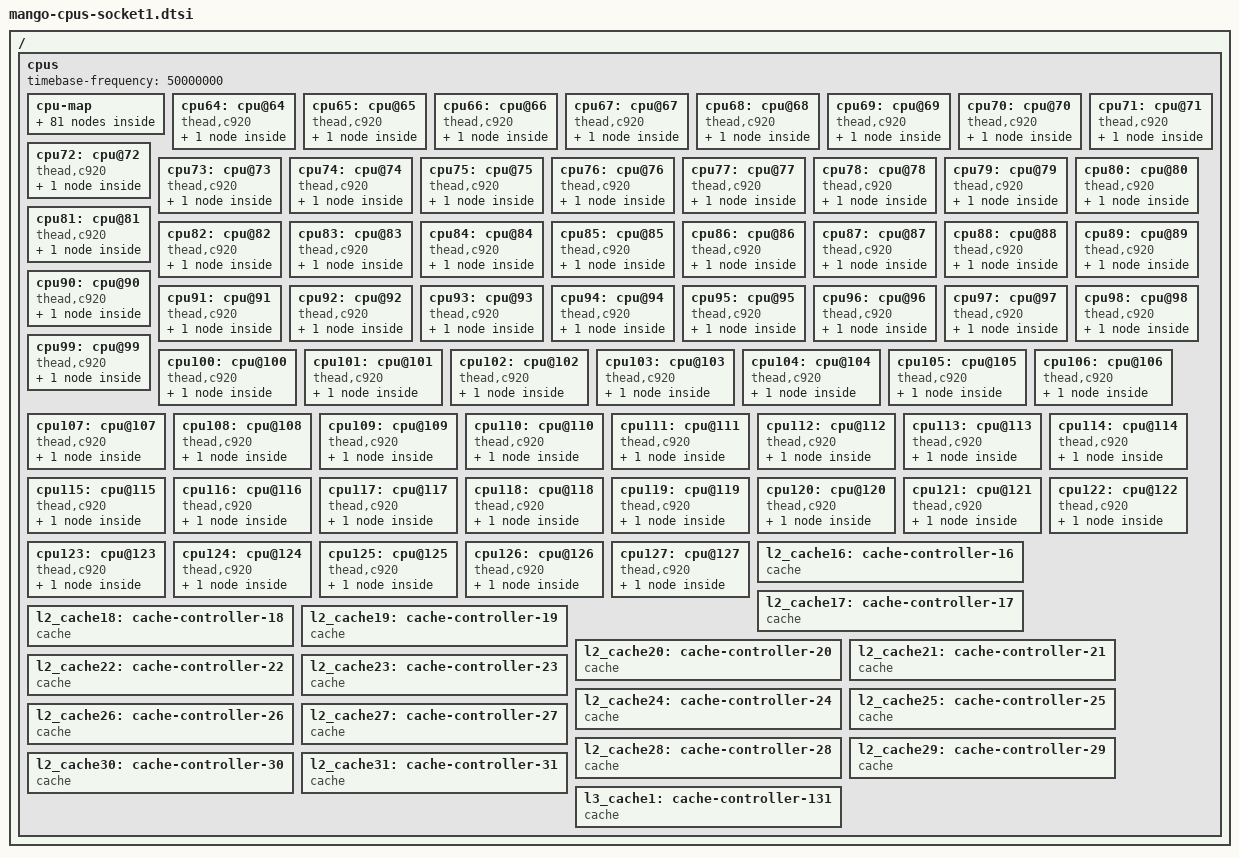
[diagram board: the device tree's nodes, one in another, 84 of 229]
// SPDX-License-Identifier: (GPL-2.0 OR MIT)
/*
 * Copyright (C) 2022 Sophgo Technology Inc. All rights reserved.
 */

/ {
	cpus {
		#address-cells = <1>;
		#size-cells = <0>;
		timebase-frequency = <50000000>;

		cpu-map {
			socket1 {
				cluster0 {
					 core0 {
						cpu = <&cpu64>;
					 };
					 core1 {
						cpu = <&cpu65>;
					 };
					 core2 {
						cpu = <&cpu66>;
					 };
					 core3 {
						cpu = <&cpu67>;
					 };
				};

				cluster1 {
					 core0 {
						cpu = <&cpu68>;
					 };
					 core1 {
						cpu = <&cpu69>;
					 };
					 core2 {
						cpu = <&cpu70>;
					 };
					 core3 {
						cpu = <&cpu71>;
					 };
				};

				cluster2 {
					 core0 {
						cpu = <&cpu80>;
					 };
					 core1 {
						cpu = <&cpu81>;
					 };
					 core2 {
						cpu = <&cpu82>;
					 };
					 core3 {
						cpu = <&cpu83>;
					 };
				};

				cluster3 {
					 core0 {
						cpu = <&cpu84>;
					 };
					 core1 {
						cpu = <&cpu85>;
					 };
					 core2 {
						cpu = <&cpu86>;
					 };
					 core3 {
						cpu = <&cpu87>;
					 };
				};

				cluster4 {
					 core0 {
						cpu = <&cpu72>;
					 };
					 core1 {
						cpu = <&cpu73>;
					 };
					 core2 {
						cpu = <&cpu74>;
					 };
					 core3 {
						cpu = <&cpu75>;
					 };
				};

				cluster5 {
					 core0 {
						cpu = <&cpu76>;
					 };
					 core1 {
						cpu = <&cpu77>;
					 };
					 core2 {
						cpu = <&cpu78>;
					 };
					 core3 {
						cpu = <&cpu79>;
					 };
				};

				cluster6 {
					 core0 {
						cpu = <&cpu88>;
					 };
					 core1 {
						cpu = <&cpu89>;
					 };
					 core2 {
						cpu = <&cpu90>;
					 };
					 core3 {
						cpu = <&cpu91>;
					 };
				};

				cluster7 {
					 core0 {
						cpu = <&cpu92>;
					 };
					 core1 {
						cpu = <&cpu93>;
					 };
					 core2 {
						cpu = <&cpu94>;
					 };
					 core3 {
						cpu = <&cpu95>;
					 };
				};

				cluster8 {
					 core0 {
						cpu = <&cpu96>;
					 };
					 core1 {
						cpu = <&cpu97>;
					 };
					 core2 {
						cpu = <&cpu98>;
					 };
					 core3 {
						cpu = <&cpu99>;
					 };
				};

				cluster9 {
					 core0 {
						cpu = <&cpu100>;
					 };
					 core1 {
						cpu = <&cpu101>;
					 };
					 core2 {
						cpu = <&cpu102>;
					 };
					 core3 {
						cpu = <&cpu103>;
					 };
				};

				cluster10 {
					 core0 {
						cpu = <&cpu112>;
					 };
					 core1 {
						cpu = <&cpu113>;
					 };
					 core2 {
						cpu = <&cpu114>;
					 };
					 core3 {
						cpu = <&cpu115>;
					 };
				};

				cluster11 {
					 core0 {
						cpu = <&cpu116>;
					 };
					 core1 {
						cpu = <&cpu117>;
					 };
					 core2 {
						cpu = <&cpu118>;
					 };
					 core3 {
						cpu = <&cpu119>;
					 };
				};

				cluster12 {
					 core0 {
						cpu = <&cpu104>;
					 };
					 core1 {
						cpu = <&cpu105>;
					 };
					 core2 {
						cpu = <&cpu106>;
					 };
					 core3 {
						cpu = <&cpu107>;
					 };
				};

				cluster13 {
					 core0 {
						cpu = <&cpu108>;
					 };
					 core1 {
						cpu = <&cpu109>;
					 };
					 core2 {
						cpu = <&cpu110>;
					 };
					 core3 {
						cpu = <&cpu111>;
					 };
				};

				cluster14 {
					 core0 {
						cpu = <&cpu120>;
					 };
					 core1 {
						cpu = <&cpu121>;
					 };
					 core2 {
						cpu = <&cpu122>;
					 };
					 core3 {
						cpu = <&cpu123>;
					 };
				};

				cluster15 {
					 core0 {
						cpu = <&cpu124>;
					 };
					 core1 {
						cpu = <&cpu125>;
					 };
					 core2 {
						cpu = <&cpu126>;
					 };
					 core3 {
						cpu = <&cpu127>;
					 };
				};
			};
		};

		cpu64: cpu@64 {
			compatible = "thead,c920", "riscv";
			device_type = "cpu";
			riscv,isa = "rv64imafdc_xtheadvector";
			riscv,isa-base = "rv64i";
			riscv,isa-extensions = "i", "m", "a", "f", "d", "c",
					       "zicntr", "zicsr", "zifencei",
					       "zihpm", "xtheadvector";
			reg = <64>;
			i-cache-size = <65536>;
			i-cache-sets = <512>;
			d-cache-block-size = <64>;
			d-cache-size = <65536>;
			d-cache-sets = <512>;
			next-level-cache = <&l2_cache16>;
			mmu-type = "riscv,sv39";
			numa-node-id = <4>;

			cpu64_intc: interrupt-controller {
				compatible = "riscv,cpu-intc";
				interrupt-controller;
				#interrupt-cells = <1>;
			};
		};

		cpu65: cpu@65 {
			compatible = "thead,c920", "riscv";
			device_type = "cpu";
			riscv,isa = "rv64imafdc_xtheadvector";
			riscv,isa-base = "rv64i";
			riscv,isa-extensions = "i", "m", "a", "f", "d", "c",
					       "zicntr", "zicsr", "zifencei",
					       "zihpm", "xtheadvector";
			reg = <65>;
			i-cache-size = <65536>;
			i-cache-sets = <512>;
			d-cache-block-size = <64>;
			d-cache-size = <65536>;
			d-cache-sets = <512>;
			next-level-cache = <&l2_cache16>;
			mmu-type = "riscv,sv39";
			numa-node-id = <4>;

			cpu65_intc: interrupt-controller {
				compatible = "riscv,cpu-intc";
				interrupt-controller;
				#interrupt-cells = <1>;
			};
		};

		cpu66: cpu@66 {
			compatible = "thead,c920", "riscv";
			device_type = "cpu";
			riscv,isa = "rv64imafdc_xtheadvector";
			riscv,isa-base = "rv64i";
			riscv,isa-extensions = "i", "m", "a", "f", "d", "c",
					       "zicntr", "zicsr", "zifencei",
					       "zihpm", "xtheadvector";
			reg = <66>;
			i-cache-size = <65536>;
			i-cache-sets = <512>;
			d-cache-block-size = <64>;
			d-cache-size = <65536>;
			d-cache-sets = <512>;
			next-level-cache = <&l2_cache16>;
			mmu-type = "riscv,sv39";
			numa-node-id = <4>;

			cpu66_intc: interrupt-controller {
				compatible = "riscv,cpu-intc";
				interrupt-controller;
				#interrupt-cells = <1>;
			};
		};

		cpu67: cpu@67 {
			compatible = "thead,c920", "riscv";
			device_type = "cpu";
			riscv,isa = "rv64imafdc_xtheadvector";
			riscv,isa-base = "rv64i";
			riscv,isa-extensions = "i", "m", "a", "f", "d", "c",
					       "zicntr", "zicsr", "zifencei",
					       "zihpm", "xtheadvector";
			reg = <67>;
			i-cache-size = <65536>;
			i-cache-sets = <512>;
			d-cache-block-size = <64>;
			d-cache-size = <65536>;
			d-cache-sets = <512>;
			next-level-cache = <&l2_cache16>;
			mmu-type = "riscv,sv39";
			numa-node-id = <4>;

			cpu67_intc: interrupt-controller {
				compatible = "riscv,cpu-intc";
				interrupt-controller;
				#interrupt-cells = <1>;
			};
		};

		cpu68: cpu@68 {
			compatible = "thead,c920", "riscv";
			device_type = "cpu";
			riscv,isa = "rv64imafdc_xtheadvector";
			riscv,isa-base = "rv64i";
			riscv,isa-extensions = "i", "m", "a", "f", "d", "c",
					       "zicntr", "zicsr", "zifencei",
					       "zihpm", "xtheadvector";
			reg = <68>;
			i-cache-size = <65536>;
			i-cache-sets = <512>;
			d-cache-block-size = <64>;
			d-cache-size = <65536>;
			d-cache-sets = <512>;
			next-level-cache = <&l2_cache17>;
			mmu-type = "riscv,sv39";
			numa-node-id = <4>;

			cpu68_intc: interrupt-controller {
				compatible = "riscv,cpu-intc";
				interrupt-controller;
				#interrupt-cells = <1>;
			};
		};

		cpu69: cpu@69 {
			compatible = "thead,c920", "riscv";
			device_type = "cpu";
			riscv,isa = "rv64imafdc_xtheadvector";
			riscv,isa-base = "rv64i";
			riscv,isa-extensions = "i", "m", "a", "f", "d", "c",
					       "zicntr", "zicsr", "zifencei",
					       "zihpm", "xtheadvector";
			reg = <69>;
			i-cache-size = <65536>;
			i-cache-sets = <512>;
			d-cache-block-size = <64>;
			d-cache-size = <65536>;
			d-cache-sets = <512>;
			next-level-cache = <&l2_cache17>;
			mmu-type = "riscv,sv39";
			numa-node-id = <4>;

			cpu69_intc: interrupt-controller {
				compatible = "riscv,cpu-intc";
				interrupt-controller;
				#interrupt-cells = <1>;
			};
		};

		cpu70: cpu@70 {
			compatible = "thead,c920", "riscv";
			device_type = "cpu";
			riscv,isa = "rv64imafdc_xtheadvector";
			riscv,isa-base = "rv64i";
			riscv,isa-extensions = "i", "m", "a", "f", "d", "c",
					       "zicntr", "zicsr", "zifencei",
					       "zihpm", "xtheadvector";
			reg = <70>;
			i-cache-size = <65536>;
			i-cache-sets = <512>;
			d-cache-block-size = <64>;
			d-cache-size = <65536>;
			d-cache-sets = <512>;
			next-level-cache = <&l2_cache17>;
			mmu-type = "riscv,sv39";
			numa-node-id = <4>;

			cpu70_intc: interrupt-controller {
				compatible = "riscv,cpu-intc";
				interrupt-controller;
				#interrupt-cells = <1>;
			};
		};

		cpu71: cpu@71 {
			compatible = "thead,c920", "riscv";
			device_type = "cpu";
			riscv,isa = "rv64imafdc_xtheadvector";
			riscv,isa-base = "rv64i";
			riscv,isa-extensions = "i", "m", "a", "f", "d", "c",
					       "zicntr", "zicsr", "zifencei",
					       "zihpm", "xtheadvector";
			reg = <71>;
			i-cache-size = <65536>;
			i-cache-sets = <512>;
			d-cache-block-size = <64>;
			d-cache-size = <65536>;
			d-cache-sets = <512>;
			next-level-cache = <&l2_cache17>;
			mmu-type = "riscv,sv39";
			numa-node-id = <4>;

			cpu71_intc: interrupt-controller {
				compatible = "riscv,cpu-intc";
				interrupt-controller;
				#interrupt-cells = <1>;
			};
		};

		cpu72: cpu@72 {
			compatible = "thead,c920", "riscv";
			device_type = "cpu";
			riscv,isa = "rv64imafdc_xtheadvector";
			riscv,isa-base = "rv64i";
			riscv,isa-extensions = "i", "m", "a", "f", "d", "c",
					       "zicntr", "zicsr", "zifencei",
					       "zihpm", "xtheadvector";
			reg = <72>;
			i-cache-size = <65536>;
			i-cache-sets = <512>;
			d-cache-block-size = <64>;
			d-cache-size = <65536>;
			d-cache-sets = <512>;
			next-level-cache = <&l2_cache20>;
			mmu-type = "riscv,sv39";
			numa-node-id = <5>;

			cpu72_intc: interrupt-controller {
				compatible = "riscv,cpu-intc";
				interrupt-controller;
				#interrupt-cells = <1>;
			};
		};

		cpu73: cpu@73 {
			compatible = "thead,c920", "riscv";
			device_type = "cpu";
			riscv,isa = "rv64imafdc_xtheadvector";
			riscv,isa-base = "rv64i";
			riscv,isa-extensions = "i", "m", "a", "f", "d", "c",
					       "zicntr", "zicsr", "zifencei",
					       "zihpm", "xtheadvector";
			reg = <73>;
			i-cache-size = <65536>;
			i-cache-sets = <512>;
			d-cache-block-size = <64>;
			d-cache-size = <65536>;
			d-cache-sets = <512>;
			next-level-cache = <&l2_cache20>;
			mmu-type = "riscv,sv39";
			numa-node-id = <5>;

			cpu73_intc: interrupt-controller {
				compatible = "riscv,cpu-intc";
				interrupt-controller;
				#interrupt-cells = <1>;
			};
		};

		cpu74: cpu@74 {
			compatible = "thead,c920", "riscv";
			device_type = "cpu";
			riscv,isa = "rv64imafdc_xtheadvector";
			riscv,isa-base = "rv64i";
			riscv,isa-extensions = "i", "m", "a", "f", "d", "c",
					       "zicntr", "zicsr", "zifencei",
					       "zihpm", "xtheadvector";
			reg = <74>;
			i-cache-size = <65536>;
			i-cache-sets = <512>;
			d-cache-block-size = <64>;
			d-cache-size = <65536>;
			d-cache-sets = <512>;
			next-level-cache = <&l2_cache20>;
			mmu-type = "riscv,sv39";
			numa-node-id = <5>;

			cpu74_intc: interrupt-controller {
				compatible = "riscv,cpu-intc";
				interrupt-controller;
				#interrupt-cells = <1>;
			};
		};

		cpu75: cpu@75 {
			compatible = "thead,c920", "riscv";
			device_type = "cpu";
			riscv,isa = "rv64imafdc_xtheadvector";
			riscv,isa-base = "rv64i";
			riscv,isa-extensions = "i", "m", "a", "f", "d", "c",
					       "zicntr", "zicsr", "zifencei",
					       "zihpm", "xtheadvector";
			reg = <75>;
			i-cache-size = <65536>;
			i-cache-sets = <512>;
			d-cache-block-size = <64>;
			d-cache-size = <65536>;
			d-cache-sets = <512>;
			next-level-cache = <&l2_cache20>;
			mmu-type = "riscv,sv39";
			numa-node-id = <5>;

			cpu75_intc: interrupt-controller {
				compatible = "riscv,cpu-intc";
				interrupt-controller;
				#interrupt-cells = <1>;
			};
		};

		cpu76: cpu@76 {
			compatible = "thead,c920", "riscv";
			device_type = "cpu";
			riscv,isa = "rv64imafdc_xtheadvector";
			riscv,isa-base = "rv64i";
			riscv,isa-extensions = "i", "m", "a", "f", "d", "c",
					       "zicntr", "zicsr", "zifencei",
					       "zihpm", "xtheadvector";
			reg = <76>;
			i-cache-size = <65536>;
			i-cache-sets = <512>;
			d-cache-block-size = <64>;
			d-cache-size = <65536>;
			d-cache-sets = <512>;
			next-level-cache = <&l2_cache21>;
			mmu-type = "riscv,sv39";
			numa-node-id = <5>;

			cpu76_intc: interrupt-controller {
				compatible = "riscv,cpu-intc";
				interrupt-controller;
				#interrupt-cells = <1>;
			};
		};

		cpu77: cpu@77 {
			compatible = "thead,c920", "riscv";
			device_type = "cpu";
			riscv,isa = "rv64imafdc_xtheadvector";
			riscv,isa-base = "rv64i";
			riscv,isa-extensions = "i", "m", "a", "f", "d", "c",
					       "zicntr", "zicsr", "zifencei",
					       "zihpm", "xtheadvector";
			reg = <77>;
			i-cache-size = <65536>;
			i-cache-sets = <512>;
			d-cache-block-size = <64>;
			d-cache-size = <65536>;
			d-cache-sets = <512>;
			next-level-cache = <&l2_cache21>;
			mmu-type = "riscv,sv39";
			numa-node-id = <5>;

			cpu77_intc: interrupt-controller {
				compatible = "riscv,cpu-intc";
				interrupt-controller;
				#interrupt-cells = <1>;
			};
		};

		cpu78: cpu@78 {
			compatible = "thead,c920", "riscv";
			device_type = "cpu";
			riscv,isa = "rv64imafdc_xtheadvector";
			riscv,isa-base = "rv64i";
			riscv,isa-extensions = "i", "m", "a", "f", "d", "c",
					       "zicntr", "zicsr", "zifencei",
					       "zihpm", "xtheadvector";
			reg = <78>;
			i-cache-size = <65536>;
			i-cache-sets = <512>;
			d-cache-block-size = <64>;
			d-cache-size = <65536>;
			d-cache-sets = <512>;
			next-level-cache = <&l2_cache21>;
			mmu-type = "riscv,sv39";
			numa-node-id = <5>;

			cpu78_intc: interrupt-controller {
				compatible = "riscv,cpu-intc";
				interrupt-controller;
				#interrupt-cells = <1>;
			};
		};

		cpu79: cpu@79 {
			compatible = "thead,c920", "riscv";
			device_type = "cpu";
			riscv,isa = "rv64imafdc_xtheadvector";
			riscv,isa-base = "rv64i";
			riscv,isa-extensions = "i", "m", "a", "f", "d", "c",
					       "zicntr", "zicsr", "zifencei",
					       "zihpm", "xtheadvector";
			reg = <79>;
			i-cache-size = <65536>;
			i-cache-sets = <512>;
			d-cache-block-size = <64>;
			d-cache-size = <65536>;
			d-cache-sets = <512>;
			next-level-cache = <&l2_cache21>;
			mmu-type = "riscv,sv39";
			numa-node-id = <5>;

			cpu79_intc: interrupt-controller {
				compatible = "riscv,cpu-intc";
				interrupt-controller;
				#interrupt-cells = <1>;
			};
		};

		cpu80: cpu@80 {
			compatible = "thead,c920", "riscv";
			device_type = "cpu";
			riscv,isa = "rv64imafdc_xtheadvector";
			riscv,isa-base = "rv64i";
			riscv,isa-extensions = "i", "m", "a", "f", "d", "c",
					       "zicntr", "zicsr", "zifencei",
					       "zihpm", "xtheadvector";
			reg = <80>;
			i-cache-size = <65536>;
			i-cache-sets = <512>;
			d-cache-block-size = <64>;
			d-cache-size = <65536>;
			d-cache-sets = <512>;
			next-level-cache = <&l2_cache18>;
			mmu-type = "riscv,sv39";
			numa-node-id = <4>;

			cpu80_intc: interrupt-controller {
				compatible = "riscv,cpu-intc";
				interrupt-controller;
				#interrupt-cells = <1>;
			};
		};

		cpu81: cpu@81 {
			compatible = "thead,c920", "riscv";
			device_type = "cpu";
			riscv,isa = "rv64imafdc_xtheadvector";
			riscv,isa-base = "rv64i";
			riscv,isa-extensions = "i", "m", "a", "f", "d", "c",
					       "zicntr", "zicsr", "zifencei",
					       "zihpm", "xtheadvector";
			reg = <81>;
			i-cache-size = <65536>;
			i-cache-sets = <512>;
			d-cache-block-size = <64>;
			d-cache-size = <65536>;
			d-cache-sets = <512>;
			next-level-cache = <&l2_cache18>;
			mmu-type = "riscv,sv39";
			numa-node-id = <4>;

			cpu81_intc: interrupt-controller {
				compatible = "riscv,cpu-intc";
				interrupt-controller;
				#interrupt-cells = <1>;
			};
		};

		cpu82: cpu@82 {
			compatible = "thead,c920", "riscv";
			device_type = "cpu";
			riscv,isa = "rv64imafdc_xtheadvector";
			riscv,isa-base = "rv64i";
			riscv,isa-extensions = "i", "m", "a", "f", "d", "c",
					       "zicntr", "zicsr", "zifencei",
					       "zihpm", "xtheadvector";
			reg = <82>;
			i-cache-size = <65536>;
			i-cache-sets = <512>;
			d-cache-block-size = <64>;
			d-cache-size = <65536>;
			d-cache-sets = <512>;
			next-level-cache = <&l2_cache18>;
			mmu-type = "riscv,sv39";
			numa-node-id = <4>;

			cpu82_intc: interrupt-controller {
				compatible = "riscv,cpu-intc";
				interrupt-controller;
				#interrupt-cells = <1>;
			};
		};

		cpu83: cpu@83 {
			compatible = "thead,c920", "riscv";
			device_type = "cpu";
			riscv,isa = "rv64imafdc_xtheadvector";
			riscv,isa-base = "rv64i";
			riscv,isa-extensions = "i", "m", "a", "f", "d", "c",
					       "zicntr", "zicsr", "zifencei",
					       "zihpm", "xtheadvector";
			reg = <83>;
			i-cache-size = <65536>;
			i-cache-sets = <512>;
			d-cache-block-size = <64>;
			d-cache-size = <65536>;
			d-cache-sets = <512>;
			next-level-cache = <&l2_cache18>;
			mmu-type = "riscv,sv39";
			numa-node-id = <4>;

			cpu83_intc: interrupt-controller {
				compatible = "riscv,cpu-intc";
				interrupt-controller;
				#interrupt-cells = <1>;
			};
		};

		cpu84: cpu@84 {
			compatible = "thead,c920", "riscv";
			device_type = "cpu";
			riscv,isa = "rv64imafdc_xtheadvector";
			riscv,isa-base = "rv64i";
			riscv,isa-extensions = "i", "m", "a", "f", "d", "c",
					       "zicntr", "zicsr", "zifencei",
					       "zihpm", "xtheadvector";
			reg = <84>;
			i-cache-size = <65536>;
			i-cache-sets = <512>;
			d-cache-block-size = <64>;
			d-cache-size = <65536>;
			d-cache-sets = <512>;
			next-level-cache = <&l2_cache19>;
			mmu-type = "riscv,sv39";
			numa-node-id = <4>;

			cpu84_intc: interrupt-controller {
				compatible = "riscv,cpu-intc";
				interrupt-controller;
				#interrupt-cells = <1>;
			};
		};

		cpu85: cpu@85 {
			compatible = "thead,c920", "riscv";
			device_type = "cpu";
			riscv,isa = "rv64imafdc_xtheadvector";
			riscv,isa-base = "rv64i";
			riscv,isa-extensions = "i", "m", "a", "f", "d", "c",
					       "zicntr", "zicsr", "zifencei",
					       "zihpm", "xtheadvector";
			reg = <85>;
			i-cache-size = <65536>;
			i-cache-sets = <512>;
			d-cache-block-size = <64>;
			d-cache-size = <65536>;
			d-cache-sets = <512>;
			next-level-cache = <&l2_cache19>;
			mmu-type = "riscv,sv39";
			numa-node-id = <4>;

			cpu85_intc: interrupt-controller {
				compatible = "riscv,cpu-intc";
				interrupt-controller;
				#interrupt-cells = <1>;
			};
		};

		cpu86: cpu@86 {
			compatible = "thead,c920", "riscv";
			device_type = "cpu";
			riscv,isa = "rv64imafdc_xtheadvector";
			riscv,isa-base = "rv64i";
			riscv,isa-extensions = "i", "m", "a", "f", "d", "c",
					       "zicntr", "zicsr", "zifencei",
					       "zihpm", "xtheadvector";
			reg = <86>;
			i-cache-size = <65536>;
			i-cache-sets = <512>;
			d-cache-block-size = <64>;
			d-cache-size = <65536>;
			d-cache-sets = <512>;
			next-level-cache = <&l2_cache19>;
			mmu-type = "riscv,sv39";
			numa-node-id = <4>;

			cpu86_intc: interrupt-controller {
				compatible = "riscv,cpu-intc";
				interrupt-controller;
				#interrupt-cells = <1>;
			};
		};

		cpu87: cpu@87 {
			compatible = "thead,c920", "riscv";
			device_type = "cpu";
			riscv,isa = "rv64imafdc_xtheadvector";
			riscv,isa-base = "rv64i";
			riscv,isa-extensions = "i", "m", "a", "f", "d", "c",
					       "zicntr", "zicsr", "zifencei",
					       "zihpm", "xtheadvector";
			reg = <87>;
			i-cache-block-size = <64>;
			i-cache-size = <65536>;
			i-cache-sets = <512>;
			d-cache-block-size = <64>;
			d-cache-size = <65536>;
			d-cache-sets = <512>;
			next-level-cache = <&l2_cache19>;
			mmu-type = "riscv,sv39";
			numa-node-id = <4>;

			cpu87_intc: interrupt-controller {
				compatible = "riscv,cpu-intc";
				interrupt-controller;
				#interrupt-cells = <1>;
			};
		};

		cpu88: cpu@88 {
			compatible = "thead,c920", "riscv";
			device_type = "cpu";
			riscv,isa = "rv64imafdc_xtheadvector";
			riscv,isa-base = "rv64i";
			riscv,isa-extensions = "i", "m", "a", "f", "d", "c",
					       "zicntr", "zicsr", "zifencei",
					       "zihpm", "xtheadvector";
			reg = <88>;
			i-cache-size = <65536>;
			i-cache-sets = <512>;
			d-cache-block-size = <64>;
			d-cache-size = <65536>;
			d-cache-sets = <512>;
			next-level-cache = <&l2_cache22>;
			mmu-type = "riscv,sv39";
			numa-node-id = <5>;

			cpu88_intc: interrupt-controller {
				compatible = "riscv,cpu-intc";
				interrupt-controller;
				#interrupt-cells = <1>;
			};
		};

		cpu89: cpu@89 {
			compatible = "thead,c920", "riscv";
			device_type = "cpu";
			riscv,isa = "rv64imafdc_xtheadvector";
			riscv,isa-base = "rv64i";
			riscv,isa-extensions = "i", "m", "a", "f", "d", "c",
					       "zicntr", "zicsr", "zifencei",
					       "zihpm", "xtheadvector";
			reg = <89>;
			i-cache-size = <65536>;
			i-cache-sets = <512>;
			d-cache-block-size = <64>;
			d-cache-size = <65536>;
			d-cache-sets = <512>;
			next-level-cache = <&l2_cache22>;
			mmu-type = "riscv,sv39";
			numa-node-id = <5>;

			cpu89_intc: interrupt-controller {
				compatible = "riscv,cpu-intc";
				interrupt-controller;
				#interrupt-cells = <1>;
			};
		};

		cpu90: cpu@90 {
			compatible = "thead,c920", "riscv";
			device_type = "cpu";
			riscv,isa = "rv64imafdc_xtheadvector";
			riscv,isa-base = "rv64i";
			riscv,isa-extensions = "i", "m", "a", "f", "d", "c",
					       "zicntr", "zicsr", "zifencei",
					       "zihpm", "xtheadvector";
			reg = <90>;
			i-cache-size = <65536>;
			i-cache-sets = <512>;
			d-cache-block-size = <64>;
			d-cache-size = <65536>;
			d-cache-sets = <512>;
			next-level-cache = <&l2_cache22>;
			mmu-type = "riscv,sv39";
			numa-node-id = <5>;

			cpu90_intc: interrupt-controller {
				compatible = "riscv,cpu-intc";
				interrupt-controller;
				#interrupt-cells = <1>;
			};
		};

		cpu91: cpu@91 {
			compatible = "thead,c920", "riscv";
			device_type = "cpu";
			riscv,isa = "rv64imafdc_xtheadvector";
			riscv,isa-base = "rv64i";
			riscv,isa-extensions = "i", "m", "a", "f", "d", "c",
					       "zicntr", "zicsr", "zifencei",
					       "zihpm", "xtheadvector";
			reg = <91>;
			i-cache-size = <65536>;
			i-cache-sets = <512>;
			d-cache-block-size = <64>;
			d-cache-size = <65536>;
			d-cache-sets = <512>;
			next-level-cache = <&l2_cache22>;
			mmu-type = "riscv,sv39";
			numa-node-id = <5>;

			cpu91_intc: interrupt-controller {
				compatible = "riscv,cpu-intc";
				interrupt-controller;
				#interrupt-cells = <1>;
			};
		};

		cpu92: cpu@92 {
			compatible = "thead,c920", "riscv";
			device_type = "cpu";
			riscv,isa = "rv64imafdc_xtheadvector";
			riscv,isa-base = "rv64i";
			riscv,isa-extensions = "i", "m", "a", "f", "d", "c",
					       "zicntr", "zicsr", "zifencei",
					       "zihpm", "xtheadvector";
			reg = <92>;
			i-cache-size = <65536>;
			i-cache-sets = <512>;
			d-cache-block-size = <64>;
			d-cache-size = <65536>;
			d-cache-sets = <512>;
			next-level-cache = <&l2_cache23>;
			mmu-type = "riscv,sv39";
			numa-node-id = <5>;

			cpu92_intc: interrupt-controller {
				compatible = "riscv,cpu-intc";
				interrupt-controller;
				#interrupt-cells = <1>;
			};
		};

		cpu93: cpu@93 {
			compatible = "thead,c920", "riscv";
			device_type = "cpu";
			riscv,isa = "rv64imafdc_xtheadvector";
			riscv,isa-base = "rv64i";
			riscv,isa-extensions = "i", "m", "a", "f", "d", "c",
					       "zicntr", "zicsr", "zifencei",
					       "zihpm", "xtheadvector";
			reg = <93>;
			i-cache-size = <65536>;
			i-cache-sets = <512>;
			d-cache-block-size = <64>;
			d-cache-size = <65536>;
			d-cache-sets = <512>;
			next-level-cache = <&l2_cache23>;
			mmu-type = "riscv,sv39";
			numa-node-id = <5>;

			cpu93_intc: interrupt-controller {
				compatible = "riscv,cpu-intc";
				interrupt-controller;
				#interrupt-cells = <1>;
			};
		};

		cpu94: cpu@94 {
			compatible = "thead,c920", "riscv";
			device_type = "cpu";
			riscv,isa = "rv64imafdc_xtheadvector";
			riscv,isa-base = "rv64i";
			riscv,isa-extensions = "i", "m", "a", "f", "d", "c",
					       "zicntr", "zicsr", "zifencei",
					       "zihpm", "xtheadvector";
			reg = <94>;
			i-cache-size = <65536>;
			i-cache-sets = <512>;
			d-cache-block-size = <64>;
			d-cache-size = <65536>;
			d-cache-sets = <512>;
			next-level-cache = <&l2_cache23>;
			mmu-type = "riscv,sv39";
			numa-node-id = <5>;

			cpu94_intc: interrupt-controller {
				compatible = "riscv,cpu-intc";
				interrupt-controller;
				#interrupt-cells = <1>;
			};
		};

		cpu95: cpu@95 {
			compatible = "thead,c920", "riscv";
			device_type = "cpu";
			riscv,isa = "rv64imafdc_xtheadvector";
			riscv,isa-base = "rv64i";
			riscv,isa-extensions = "i", "m", "a", "f", "d", "c",
					       "zicntr", "zicsr", "zifencei",
					       "zihpm", "xtheadvector";
			reg = <95>;
			i-cache-block-size = <64>;
			i-cache-size = <65536>;
			i-cache-sets = <512>;
			d-cache-block-size = <64>;
			d-cache-size = <65536>;
			d-cache-sets = <512>;
			next-level-cache = <&l2_cache23>;
			mmu-type = "riscv,sv39";
			numa-node-id = <5>;

			cpu95_intc: interrupt-controller {
				compatible = "riscv,cpu-intc";
				interrupt-controller;
				#interrupt-cells = <1>;
			};
		};

		cpu96: cpu@96 {
			compatible = "thead,c920", "riscv";
			device_type = "cpu";
			riscv,isa = "rv64imafdc_xtheadvector";
			riscv,isa-base = "rv64i";
			riscv,isa-extensions = "i", "m", "a", "f", "d", "c",
					       "zicntr", "zicsr", "zifencei",
					       "zihpm", "xtheadvector";
			reg = <96>;
			i-cache-size = <65536>;
			i-cache-sets = <512>;
			d-cache-block-size = <64>;
			d-cache-size = <65536>;
			d-cache-sets = <512>;
			next-level-cache = <&l2_cache24>;
			mmu-type = "riscv,sv39";
			numa-node-id = <6>;

			cpu96_intc: interrupt-controller {
				compatible = "riscv,cpu-intc";
				interrupt-controller;
				#interrupt-cells = <1>;
			};
		};

		cpu97: cpu@97 {
			compatible = "thead,c920", "riscv";
			device_type = "cpu";
			riscv,isa = "rv64imafdc_xtheadvector";
			riscv,isa-base = "rv64i";
			riscv,isa-extensions = "i", "m", "a", "f", "d", "c",
					       "zicntr", "zicsr", "zifencei",
					       "zihpm", "xtheadvector";
			reg = <97>;
			i-cache-size = <65536>;
			i-cache-sets = <512>;
			d-cache-block-size = <64>;
			d-cache-size = <65536>;
			d-cache-sets = <512>;
			next-level-cache = <&l2_cache24>;
			mmu-type = "riscv,sv39";
			numa-node-id = <6>;

			cpu97_intc: interrupt-controller {
				compatible = "riscv,cpu-intc";
				interrupt-controller;
				#interrupt-cells = <1>;
			};
		};

		cpu98: cpu@98 {
			compatible = "thead,c920", "riscv";
			device_type = "cpu";
			riscv,isa = "rv64imafdc_xtheadvector";
			riscv,isa-base = "rv64i";
			riscv,isa-extensions = "i", "m", "a", "f", "d", "c",
					       "zicntr", "zicsr", "zifencei",
					       "zihpm", "xtheadvector";
			reg = <98>;
			i-cache-size = <65536>;
			i-cache-sets = <512>;
			d-cache-block-size = <64>;
			d-cache-size = <65536>;
			d-cache-sets = <512>;
			next-level-cache = <&l2_cache24>;
			mmu-type = "riscv,sv39";
			numa-node-id = <6>;

			cpu98_intc: interrupt-controller {
				compatible = "riscv,cpu-intc";
				interrupt-controller;
				#interrupt-cells = <1>;
			};
		};

		cpu99: cpu@99 {
			compatible = "thead,c920", "riscv";
			device_type = "cpu";
			riscv,isa = "rv64imafdc_xtheadvector";
			riscv,isa-base = "rv64i";
			riscv,isa-extensions = "i", "m", "a", "f", "d", "c",
					       "zicntr", "zicsr", "zifencei",
					       "zihpm", "xtheadvector";
			reg = <99>;
			i-cache-size = <65536>;
			i-cache-sets = <512>;
			d-cache-block-size = <64>;
			d-cache-size = <65536>;
			d-cache-sets = <512>;
			next-level-cache = <&l2_cache24>;
			mmu-type = "riscv,sv39";
			numa-node-id = <6>;

			cpu99_intc: interrupt-controller {
				compatible = "riscv,cpu-intc";
				interrupt-controller;
				#interrupt-cells = <1>;
			};
		};

		cpu100: cpu@100 {
			compatible = "thead,c920", "riscv";
			device_type = "cpu";
			riscv,isa = "rv64imafdc_xtheadvector";
			riscv,isa-base = "rv64i";
			riscv,isa-extensions = "i", "m", "a", "f", "d", "c",
					       "zicntr", "zicsr", "zifencei",
					       "zihpm", "xtheadvector";
			reg = <100>;
			i-cache-size = <65536>;
			i-cache-sets = <512>;
			d-cache-block-size = <64>;
			d-cache-size = <65536>;
			d-cache-sets = <512>;
			next-level-cache = <&l2_cache25>;
			mmu-type = "riscv,sv39";
			numa-node-id = <6>;

			cpu100_intc: interrupt-controller {
				compatible = "riscv,cpu-intc";
				interrupt-controller;
				#interrupt-cells = <1>;
			};
		};

		cpu101: cpu@101 {
			compatible = "thead,c920", "riscv";
			device_type = "cpu";
			riscv,isa = "rv64imafdc_xtheadvector";
			riscv,isa-base = "rv64i";
			riscv,isa-extensions = "i", "m", "a", "f", "d", "c",
					       "zicntr", "zicsr", "zifencei",
					       "zihpm", "xtheadvector";
			reg = <101>;
			i-cache-size = <65536>;
			i-cache-sets = <512>;
			d-cache-block-size = <64>;
			d-cache-size = <65536>;
			d-cache-sets = <512>;
			next-level-cache = <&l2_cache25>;
			mmu-type = "riscv,sv39";
			numa-node-id = <6>;

			cpu101_intc: interrupt-controller {
				compatible = "riscv,cpu-intc";
				interrupt-controller;
				#interrupt-cells = <1>;
			};
		};

		cpu102: cpu@102 {
			compatible = "thead,c920", "riscv";
			device_type = "cpu";
			riscv,isa = "rv64imafdc_xtheadvector";
			riscv,isa-base = "rv64i";
			riscv,isa-extensions = "i", "m", "a", "f", "d", "c",
					       "zicntr", "zicsr", "zifencei",
					       "zihpm", "xtheadvector";
			reg = <102>;
			i-cache-size = <65536>;
			i-cache-sets = <512>;
			d-cache-block-size = <64>;
			d-cache-size = <65536>;
			d-cache-sets = <512>;
			next-level-cache = <&l2_cache25>;
			mmu-type = "riscv,sv39";
			numa-node-id = <6>;

			cpu102_intc: interrupt-controller {
				compatible = "riscv,cpu-intc";
				interrupt-controller;
				#interrupt-cells = <1>;
			};
		};

		cpu103: cpu@103 {
			compatible = "thead,c920", "riscv";
			device_type = "cpu";
			riscv,isa = "rv64imafdc_xtheadvector";
			riscv,isa-base = "rv64i";
			riscv,isa-extensions = "i", "m", "a", "f", "d", "c",
					       "zicntr", "zicsr", "zifencei",
					       "zihpm", "xtheadvector";
			reg = <103>;
			i-cache-size = <65536>;
			i-cache-sets = <512>;
			d-cache-block-size = <64>;
			d-cache-size = <65536>;
			d-cache-sets = <512>;
			next-level-cache = <&l2_cache25>;
			mmu-type = "riscv,sv39";
			numa-node-id = <6>;

			cpu103_intc: interrupt-controller {
				compatible = "riscv,cpu-intc";
				interrupt-controller;
				#interrupt-cells = <1>;
			};
		};

		cpu104: cpu@104 {
			compatible = "thead,c920", "riscv";
			device_type = "cpu";
			riscv,isa = "rv64imafdc_xtheadvector";
			riscv,isa-base = "rv64i";
			riscv,isa-extensions = "i", "m", "a", "f", "d", "c",
					       "zicntr", "zicsr", "zifencei",
					       "zihpm", "xtheadvector";
			reg = <104>;
			i-cache-size = <65536>;
			i-cache-sets = <512>;
			d-cache-block-size = <64>;
			d-cache-size = <65536>;
			d-cache-sets = <512>;
			next-level-cache = <&l2_cache28>;
			mmu-type = "riscv,sv39";
			numa-node-id = <7>;

			cpu104_intc: interrupt-controller {
				compatible = "riscv,cpu-intc";
				interrupt-controller;
				#interrupt-cells = <1>;
			};
		};

		cpu105: cpu@105 {
			compatible = "thead,c920", "riscv";
			device_type = "cpu";
			riscv,isa = "rv64imafdc_xtheadvector";
			riscv,isa-base = "rv64i";
			riscv,isa-extensions = "i", "m", "a", "f", "d", "c",
					       "zicntr", "zicsr", "zifencei",
					       "zihpm", "xtheadvector";
			reg = <105>;
			i-cache-size = <65536>;
			i-cache-sets = <512>;
			d-cache-block-size = <64>;
			d-cache-size = <65536>;
			d-cache-sets = <512>;
			next-level-cache = <&l2_cache28>;
			mmu-type = "riscv,sv39";
			numa-node-id = <7>;

			cpu105_intc: interrupt-controller {
				compatible = "riscv,cpu-intc";
				interrupt-controller;
				#interrupt-cells = <1>;
			};
		};

		cpu106: cpu@106 {
			compatible = "thead,c920", "riscv";
			device_type = "cpu";
			riscv,isa = "rv64imafdc_xtheadvector";
			riscv,isa-base = "rv64i";
			riscv,isa-extensions = "i", "m", "a", "f", "d", "c",
					       "zicntr", "zicsr", "zifencei",
					       "zihpm", "xtheadvector";
			reg = <106>;
			i-cache-size = <65536>;
			i-cache-sets = <512>;
			d-cache-block-size = <64>;
			d-cache-size = <65536>;
			d-cache-sets = <512>;
			next-level-cache = <&l2_cache28>;
			mmu-type = "riscv,sv39";
			numa-node-id = <7>;

			cpu106_intc: interrupt-controller {
				compatible = "riscv,cpu-intc";
				interrupt-controller;
				#interrupt-cells = <1>;
			};
		};

		cpu107: cpu@107 {
			compatible = "thead,c920", "riscv";
			device_type = "cpu";
			riscv,isa = "rv64imafdc_xtheadvector";
			riscv,isa-base = "rv64i";
			riscv,isa-extensions = "i", "m", "a", "f", "d", "c",
					       "zicntr", "zicsr", "zifencei",
					       "zihpm", "xtheadvector";
			reg = <107>;
			i-cache-size = <65536>;
			i-cache-sets = <512>;
			d-cache-block-size = <64>;
			d-cache-size = <65536>;
			d-cache-sets = <512>;
			next-level-cache = <&l2_cache28>;
			mmu-type = "riscv,sv39";
			numa-node-id = <7>;

			cpu107_intc: interrupt-controller {
				compatible = "riscv,cpu-intc";
				interrupt-controller;
				#interrupt-cells = <1>;
			};
		};

		cpu108: cpu@108 {
			compatible = "thead,c920", "riscv";
			device_type = "cpu";
			riscv,isa = "rv64imafdc_xtheadvector";
			riscv,isa-base = "rv64i";
			riscv,isa-extensions = "i", "m", "a", "f", "d", "c",
					       "zicntr", "zicsr", "zifencei",
					       "zihpm", "xtheadvector";
			reg = <108>;
			i-cache-size = <65536>;
			i-cache-sets = <512>;
			d-cache-block-size = <64>;
			d-cache-size = <65536>;
			d-cache-sets = <512>;
			next-level-cache = <&l2_cache29>;
			mmu-type = "riscv,sv39";
			numa-node-id = <7>;

			cpu108_intc: interrupt-controller {
				compatible = "riscv,cpu-intc";
				interrupt-controller;
				#interrupt-cells = <1>;
			};
		};

		cpu109: cpu@109 {
			compatible = "thead,c920", "riscv";
			device_type = "cpu";
			riscv,isa = "rv64imafdc_xtheadvector";
			riscv,isa-base = "rv64i";
			riscv,isa-extensions = "i", "m", "a", "f", "d", "c",
					       "zicntr", "zicsr", "zifencei",
					       "zihpm", "xtheadvector";
			reg = <109>;
			i-cache-size = <65536>;
			i-cache-sets = <512>;
			d-cache-block-size = <64>;
			d-cache-size = <65536>;
			d-cache-sets = <512>;
			next-level-cache = <&l2_cache29>;
			mmu-type = "riscv,sv39";
			numa-node-id = <7>;

			cpu109_intc: interrupt-controller {
				compatible = "riscv,cpu-intc";
				interrupt-controller;
				#interrupt-cells = <1>;
			};
		};

		cpu110: cpu@110 {
			compatible = "thead,c920", "riscv";
			device_type = "cpu";
			riscv,isa = "rv64imafdc_xtheadvector";
			riscv,isa-base = "rv64i";
			riscv,isa-extensions = "i", "m", "a", "f", "d", "c",
					       "zicntr", "zicsr", "zifencei",
					       "zihpm", "xtheadvector";
			reg = <110>;
			i-cache-size = <65536>;
			i-cache-sets = <512>;
			d-cache-block-size = <64>;
			d-cache-size = <65536>;
			d-cache-sets = <512>;
			next-level-cache = <&l2_cache29>;
			mmu-type = "riscv,sv39";
			numa-node-id = <7>;

			cpu110_intc: interrupt-controller {
				compatible = "riscv,cpu-intc";
				interrupt-controller;
				#interrupt-cells = <1>;
			};
		};

		cpu111: cpu@111 {
			compatible = "thead,c920", "riscv";
			device_type = "cpu";
			riscv,isa = "rv64imafdc_xtheadvector";
			riscv,isa-base = "rv64i";
			riscv,isa-extensions = "i", "m", "a", "f", "d", "c",
					       "zicntr", "zicsr", "zifencei",
					       "zihpm", "xtheadvector";
			reg = <111>;
			i-cache-size = <65536>;
			i-cache-sets = <512>;
			d-cache-block-size = <64>;
			d-cache-size = <65536>;
			d-cache-sets = <512>;
			next-level-cache = <&l2_cache29>;
			mmu-type = "riscv,sv39";
			numa-node-id = <7>;

			cpu111_intc: interrupt-controller {
				compatible = "riscv,cpu-intc";
				interrupt-controller;
				#interrupt-cells = <1>;
			};
		};

		cpu112: cpu@112 {
			compatible = "thead,c920", "riscv";
			device_type = "cpu";
			riscv,isa = "rv64imafdc_xtheadvector";
			riscv,isa-base = "rv64i";
			riscv,isa-extensions = "i", "m", "a", "f", "d", "c",
					       "zicntr", "zicsr", "zifencei",
					       "zihpm", "xtheadvector";
			reg = <112>;
			i-cache-size = <65536>;
			i-cache-sets = <512>;
			d-cache-block-size = <64>;
			d-cache-size = <65536>;
			d-cache-sets = <512>;
			next-level-cache = <&l2_cache26>;
			mmu-type = "riscv,sv39";
			numa-node-id = <6>;

			cpu112_intc: interrupt-controller {
				compatible = "riscv,cpu-intc";
				interrupt-controller;
				#interrupt-cells = <1>;
			};
		};

		cpu113: cpu@113 {
			compatible = "thead,c920", "riscv";
			device_type = "cpu";
			riscv,isa = "rv64imafdc_xtheadvector";
			riscv,isa-base = "rv64i";
			riscv,isa-extensions = "i", "m", "a", "f", "d", "c",
					       "zicntr", "zicsr", "zifencei",
					       "zihpm", "xtheadvector";
			reg = <113>;
			i-cache-size = <65536>;
			i-cache-sets = <512>;
			d-cache-block-size = <64>;
			d-cache-size = <65536>;
			d-cache-sets = <512>;
			next-level-cache = <&l2_cache26>;
			mmu-type = "riscv,sv39";
			numa-node-id = <6>;

			cpu113_intc: interrupt-controller {
				compatible = "riscv,cpu-intc";
				interrupt-controller;
				#interrupt-cells = <1>;
			};
		};

		cpu114: cpu@114 {
			compatible = "thead,c920", "riscv";
			device_type = "cpu";
			riscv,isa = "rv64imafdc_xtheadvector";
			riscv,isa-base = "rv64i";
			riscv,isa-extensions = "i", "m", "a", "f", "d", "c",
					       "zicntr", "zicsr", "zifencei",
					       "zihpm", "xtheadvector";
			reg = <114>;
			i-cache-size = <65536>;
			i-cache-sets = <512>;
			d-cache-block-size = <64>;
			d-cache-size = <65536>;
			d-cache-sets = <512>;
			next-level-cache = <&l2_cache26>;
			mmu-type = "riscv,sv39";
			numa-node-id = <6>;

			cpu114_intc: interrupt-controller {
				compatible = "riscv,cpu-intc";
				interrupt-controller;
				#interrupt-cells = <1>;
			};
		};

		cpu115: cpu@115 {
			compatible = "thead,c920", "riscv";
			device_type = "cpu";
			riscv,isa = "rv64imafdc_xtheadvector";
			riscv,isa-base = "rv64i";
			riscv,isa-extensions = "i", "m", "a", "f", "d", "c",
					       "zicntr", "zicsr", "zifencei",
					       "zihpm", "xtheadvector";
			reg = <115>;
			i-cache-size = <65536>;
			i-cache-sets = <512>;
			d-cache-block-size = <64>;
			d-cache-size = <65536>;
			d-cache-sets = <512>;
			next-level-cache = <&l2_cache26>;
			mmu-type = "riscv,sv39";
			numa-node-id = <6>;

			cpu115_intc: interrupt-controller {
				compatible = "riscv,cpu-intc";
				interrupt-controller;
				#interrupt-cells = <1>;
			};
		};

		cpu116: cpu@116 {
			compatible = "thead,c920", "riscv";
			device_type = "cpu";
			riscv,isa = "rv64imafdc_xtheadvector";
			riscv,isa-base = "rv64i";
			riscv,isa-extensions = "i", "m", "a", "f", "d", "c",
					       "zicntr", "zicsr", "zifencei",
					       "zihpm", "xtheadvector";
			reg = <116>;
			i-cache-size = <65536>;
			i-cache-sets = <512>;
			d-cache-block-size = <64>;
			d-cache-size = <65536>;
			d-cache-sets = <512>;
			next-level-cache = <&l2_cache27>;
			mmu-type = "riscv,sv39";
			numa-node-id = <6>;

			cpu116_intc: interrupt-controller {
				compatible = "riscv,cpu-intc";
				interrupt-controller;
				#interrupt-cells = <1>;
			};
		};

		cpu117: cpu@117 {
			compatible = "thead,c920", "riscv";
			device_type = "cpu";
			riscv,isa = "rv64imafdc_xtheadvector";
			riscv,isa-base = "rv64i";
			riscv,isa-extensions = "i", "m", "a", "f", "d", "c",
					       "zicntr", "zicsr", "zifencei",
					       "zihpm", "xtheadvector";
			reg = <117>;
			i-cache-size = <65536>;
			i-cache-sets = <512>;
			d-cache-block-size = <64>;
			d-cache-size = <65536>;
			d-cache-sets = <512>;
			next-level-cache = <&l2_cache27>;
			mmu-type = "riscv,sv39";
			numa-node-id = <6>;

			cpu117_intc: interrupt-controller {
				compatible = "riscv,cpu-intc";
				interrupt-controller;
				#interrupt-cells = <1>;
			};
		};

		cpu118: cpu@118 {
			compatible = "thead,c920", "riscv";
			device_type = "cpu";
			riscv,isa = "rv64imafdc_xtheadvector";
			riscv,isa-base = "rv64i";
			riscv,isa-extensions = "i", "m", "a", "f", "d", "c",
					       "zicntr", "zicsr", "zifencei",
					       "zihpm", "xtheadvector";
			reg = <118>;
			i-cache-size = <65536>;
			i-cache-sets = <512>;
			d-cache-block-size = <64>;
			d-cache-size = <65536>;
			d-cache-sets = <512>;
			next-level-cache = <&l2_cache27>;
			mmu-type = "riscv,sv39";
			numa-node-id = <6>;

			cpu118_intc: interrupt-controller {
				compatible = "riscv,cpu-intc";
				interrupt-controller;
				#interrupt-cells = <1>;
			};
		};

		cpu119: cpu@119 {
			compatible = "thead,c920", "riscv";
			device_type = "cpu";
			riscv,isa = "rv64imafdc_xtheadvector";
			riscv,isa-base = "rv64i";
			riscv,isa-extensions = "i", "m", "a", "f", "d", "c",
					       "zicntr", "zicsr", "zifencei",
					       "zihpm", "xtheadvector";
			reg = <119>;
			i-cache-block-size = <64>;
			i-cache-size = <65536>;
			i-cache-sets = <512>;
			d-cache-block-size = <64>;
			d-cache-size = <65536>;
			d-cache-sets = <512>;
			next-level-cache = <&l2_cache27>;
			mmu-type = "riscv,sv39";
			numa-node-id = <6>;

			cpu119_intc: interrupt-controller {
				compatible = "riscv,cpu-intc";
				interrupt-controller;
				#interrupt-cells = <1>;
			};
		};

		cpu120: cpu@120 {
			compatible = "thead,c920", "riscv";
			device_type = "cpu";
			riscv,isa = "rv64imafdc_xtheadvector";
			riscv,isa-base = "rv64i";
			riscv,isa-extensions = "i", "m", "a", "f", "d", "c",
					       "zicntr", "zicsr", "zifencei",
					       "zihpm", "xtheadvector";
			reg = <120>;
			i-cache-size = <65536>;
			i-cache-sets = <512>;
			d-cache-block-size = <64>;
			d-cache-size = <65536>;
			d-cache-sets = <512>;
			next-level-cache = <&l2_cache30>;
			mmu-type = "riscv,sv39";
			numa-node-id = <7>;

			cpu120_intc: interrupt-controller {
				compatible = "riscv,cpu-intc";
				interrupt-controller;
				#interrupt-cells = <1>;
			};
		};

		cpu121: cpu@121 {
			compatible = "thead,c920", "riscv";
			device_type = "cpu";
			riscv,isa = "rv64imafdc_xtheadvector";
			riscv,isa-base = "rv64i";
			riscv,isa-extensions = "i", "m", "a", "f", "d", "c",
					       "zicntr", "zicsr", "zifencei",
					       "zihpm", "xtheadvector";
			reg = <121>;
			i-cache-size = <65536>;
			i-cache-sets = <512>;
			d-cache-block-size = <64>;
			d-cache-size = <65536>;
			d-cache-sets = <512>;
			next-level-cache = <&l2_cache30>;
			mmu-type = "riscv,sv39";
			numa-node-id = <7>;

			cpu121_intc: interrupt-controller {
				compatible = "riscv,cpu-intc";
				interrupt-controller;
				#interrupt-cells = <1>;
			};
		};

		cpu122: cpu@122 {
			compatible = "thead,c920", "riscv";
			device_type = "cpu";
			riscv,isa = "rv64imafdc_xtheadvector";
			riscv,isa-base = "rv64i";
			riscv,isa-extensions = "i", "m", "a", "f", "d", "c",
					       "zicntr", "zicsr", "zifencei",
					       "zihpm", "xtheadvector";
			reg = <122>;
			i-cache-size = <65536>;
			i-cache-sets = <512>;
			d-cache-block-size = <64>;
			d-cache-size = <65536>;
			d-cache-sets = <512>;
			next-level-cache = <&l2_cache30>;
			mmu-type = "riscv,sv39";
			numa-node-id = <7>;

			cpu122_intc: interrupt-controller {
				compatible = "riscv,cpu-intc";
				interrupt-controller;
				#interrupt-cells = <1>;
			};
		};

		cpu123: cpu@123 {
			compatible = "thead,c920", "riscv";
			device_type = "cpu";
			riscv,isa = "rv64imafdc_xtheadvector";
			riscv,isa-base = "rv64i";
			riscv,isa-extensions = "i", "m", "a", "f", "d", "c",
					       "zicntr", "zicsr", "zifencei",
					       "zihpm", "xtheadvector";
			reg = <123>;
			i-cache-size = <65536>;
			i-cache-sets = <512>;
			d-cache-block-size = <64>;
			d-cache-size = <65536>;
			d-cache-sets = <512>;
			next-level-cache = <&l2_cache30>;
			mmu-type = "riscv,sv39";
			numa-node-id = <7>;

			cpu123_intc: interrupt-controller {
				compatible = "riscv,cpu-intc";
				interrupt-controller;
				#interrupt-cells = <1>;
			};
		};

		cpu124: cpu@124 {
			compatible = "thead,c920", "riscv";
			device_type = "cpu";
			riscv,isa = "rv64imafdc_xtheadvector";
			riscv,isa-base = "rv64i";
			riscv,isa-extensions = "i", "m", "a", "f", "d", "c",
					       "zicntr", "zicsr", "zifencei",
					       "zihpm", "xtheadvector";
			reg = <124>;
			i-cache-size = <65536>;
			i-cache-sets = <512>;
			d-cache-block-size = <64>;
			d-cache-size = <65536>;
			d-cache-sets = <512>;
			next-level-cache = <&l2_cache31>;
			mmu-type = "riscv,sv39";
			numa-node-id = <7>;

			cpu124_intc: interrupt-controller {
				compatible = "riscv,cpu-intc";
				interrupt-controller;
				#interrupt-cells = <1>;
			};
		};

		cpu125: cpu@125 {
			compatible = "thead,c920", "riscv";
			device_type = "cpu";
			riscv,isa = "rv64imafdc_xtheadvector";
			riscv,isa-base = "rv64i";
			riscv,isa-extensions = "i", "m", "a", "f", "d", "c",
					       "zicntr", "zicsr", "zifencei",
					       "zihpm", "xtheadvector";
			reg = <125>;
			i-cache-size = <65536>;
			i-cache-sets = <512>;
			d-cache-block-size = <64>;
			d-cache-size = <65536>;
			d-cache-sets = <512>;
			next-level-cache = <&l2_cache31>;
			mmu-type = "riscv,sv39";
			numa-node-id = <7>;

			cpu125_intc: interrupt-controller {
				compatible = "riscv,cpu-intc";
				interrupt-controller;
				#interrupt-cells = <1>;
			};
		};

		cpu126: cpu@126 {
			compatible = "thead,c920", "riscv";
			device_type = "cpu";
			riscv,isa = "rv64imafdc_xtheadvector";
			riscv,isa-base = "rv64i";
			riscv,isa-extensions = "i", "m", "a", "f", "d", "c",
					       "zicntr", "zicsr", "zifencei",
					       "zihpm", "xtheadvector";
			reg = <126>;
			i-cache-size = <65536>;
			i-cache-sets = <512>;
			d-cache-block-size = <64>;
			d-cache-size = <65536>;
			d-cache-sets = <512>;
			next-level-cache = <&l2_cache31>;
			mmu-type = "riscv,sv39";
			numa-node-id = <7>;

			cpu126_intc: interrupt-controller {
				compatible = "riscv,cpu-intc";
				interrupt-controller;
				#interrupt-cells = <1>;
			};
		};

		cpu127: cpu@127 {
			compatible = "thead,c920", "riscv";
			device_type = "cpu";
			riscv,isa = "rv64imafdc_xtheadvector";
			riscv,isa-base = "rv64i";
			riscv,isa-extensions = "i", "m", "a", "f", "d", "c",
					       "zicntr", "zicsr", "zifencei",
					       "zihpm", "xtheadvector";
			reg = <127>;
			i-cache-block-size = <64>;
			i-cache-size = <65536>;
			i-cache-sets = <512>;
			d-cache-block-size = <64>;
			d-cache-size = <65536>;
			d-cache-sets = <512>;
			next-level-cache = <&l2_cache31>;
			mmu-type = "riscv,sv39";
			numa-node-id = <7>;

			cpu127_intc: interrupt-controller {
				compatible = "riscv,cpu-intc";
				interrupt-controller;
				#interrupt-cells = <1>;
			};
		};

		l2_cache16: cache-controller-16 {
			compatible = "cache";
			cache-block-size = <64>;
			cache-level = <2>;
			cache-size = <1048576>;
			cache-sets = <1024>;
			cache-unified;
			next-level-cache = <&l3_cache1>;
		};

		l2_cache17: cache-controller-17 {
			compatible = "cache";
			cache-block-size = <64>;
			cache-level = <2>;
			cache-size = <1048576>;
			cache-sets = <1024>;
			cache-unified;
			next-level-cache = <&l3_cache1>;
		};

		l2_cache18: cache-controller-18 {
			compatible = "cache";
			cache-block-size = <64>;
			cache-level = <2>;
			cache-size = <1048576>;
			cache-sets = <1024>;
			cache-unified;
			next-level-cache = <&l3_cache1>;
		};

		l2_cache19: cache-controller-19 {
			compatible = "cache";
			cache-block-size = <64>;
			cache-level = <2>;
			cache-size = <1048576>;
			cache-sets = <1024>;
			cache-unified;
			next-level-cache = <&l3_cache1>;
		};

		l2_cache20: cache-controller-20 {
			compatible = "cache";
			cache-block-size = <64>;
			cache-level = <2>;
			cache-size = <1048576>;
			cache-sets = <1024>;
			cache-unified;
			next-level-cache = <&l3_cache1>;
		};

		l2_cache21: cache-controller-21 {
			compatible = "cache";
			cache-block-size = <64>;
			cache-level = <2>;
			cache-size = <1048576>;
			cache-sets = <1024>;
			cache-unified;
			next-level-cache = <&l3_cache1>;
		};

		l2_cache22: cache-controller-22 {
			compatible = "cache";
			cache-block-size = <64>;
			cache-level = <2>;
			cache-size = <1048576>;
			cache-sets = <1024>;
			cache-unified;
			next-level-cache = <&l3_cache1>;
		};

		l2_cache23: cache-controller-23 {
			compatible = "cache";
			cache-block-size = <64>;
			cache-level = <2>;
			cache-size = <1048576>;
			cache-sets = <1024>;
			cache-unified;
			next-level-cache = <&l3_cache1>;
		};

		l2_cache24: cache-controller-24 {
			compatible = "cache";
			cache-block-size = <64>;
			cache-level = <2>;
			cache-size = <1048576>;
			cache-sets = <1024>;
			cache-unified;
			next-level-cache = <&l3_cache1>;
		};

		l2_cache25: cache-controller-25 {
			compatible = "cache";
			cache-block-size = <64>;
			cache-level = <2>;
			cache-size = <1048576>;
			cache-sets = <1024>;
			cache-unified;
			next-level-cache = <&l3_cache1>;
		};

		l2_cache26: cache-controller-26 {
			compatible = "cache";
			cache-block-size = <64>;
			cache-level = <2>;
			cache-size = <1048576>;
			cache-sets = <1024>;
			cache-unified;
			next-level-cache = <&l3_cache1>;
		};

		l2_cache27: cache-controller-27 {
			compatible = "cache";
			cache-block-size = <64>;
			cache-level = <2>;
			cache-size = <1048576>;
			cache-sets = <1024>;
			cache-unified;
			next-level-cache = <&l3_cache1>;
		};

		l2_cache28: cache-controller-28 {
			compatible = "cache";
			cache-block-size = <64>;
			cache-level = <2>;
			cache-size = <1048576>;
			cache-sets = <1024>;
			cache-unified;
			next-level-cache = <&l3_cache1>;
		};

		l2_cache29: cache-controller-29 {
			compatible = "cache";
			cache-block-size = <64>;
			cache-level = <2>;
			cache-size = <1048576>;
			cache-sets = <1024>;
			cache-unified;
			next-level-cache = <&l3_cache1>;
		};

		l2_cache30: cache-controller-30 {
			compatible = "cache";
			cache-block-size = <64>;
			cache-level = <2>;
			cache-size = <1048576>;
			cache-sets = <1024>;
			cache-unified;
			next-level-cache = <&l3_cache1>;
		};

		l2_cache31: cache-controller-31 {
			compatible = "cache";
			cache-block-size = <64>;
			cache-level = <2>;
			cache-size = <1048576>;
			cache-sets = <1024>;
			cache-unified;
			next-level-cache = <&l3_cache1>;
		};

		l3_cache1: cache-controller-131 {
			compatible = "cache";
			cache-block-size = <64>;
			cache-level = <3>;
			cache-size = <67108864>;
			cache-sets = <4096>;
			cache-unified;
		};

	};
};
